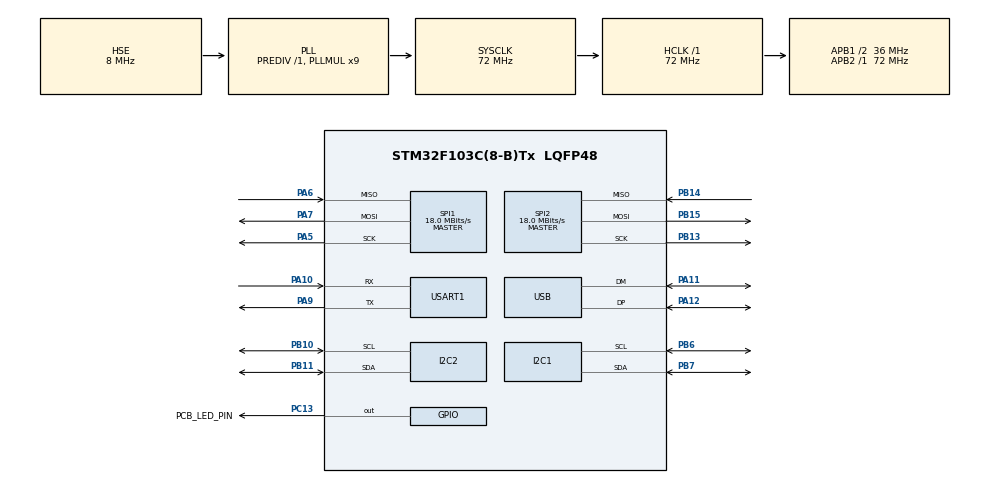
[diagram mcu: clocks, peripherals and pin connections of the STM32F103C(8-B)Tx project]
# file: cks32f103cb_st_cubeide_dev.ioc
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Dma.MEMTOMEM.0.Direction=DMA_MEMORY_TO_MEMORY
Dma.MEMTOMEM.0.Instance=DMA1_Channel1
Dma.MEMTOMEM.0.MemDataAlignment=DMA_MDATAALIGN_BYTE
Dma.MEMTOMEM.0.MemInc=DMA_MINC_ENABLE
Dma.MEMTOMEM.0.Mode=DMA_NORMAL
Dma.MEMTOMEM.0.PeriphDataAlignment=DMA_PDATAALIGN_BYTE
Dma.MEMTOMEM.0.PeriphInc=DMA_PINC_ENABLE
Dma.MEMTOMEM.0.Priority=DMA_PRIORITY_LOW
Dma.MEMTOMEM.1.Direction=DMA_MEMORY_TO_MEMORY
Dma.MEMTOMEM.1.Instance=DMA1_Channel2
Dma.MEMTOMEM.1.MemDataAlignment=DMA_MDATAALIGN_HALFWORD
Dma.MEMTOMEM.1.MemInc=DMA_MINC_ENABLE
Dma.MEMTOMEM.1.Mode=DMA_NORMAL
Dma.MEMTOMEM.1.PeriphDataAlignment=DMA_PDATAALIGN_HALFWORD
Dma.MEMTOMEM.1.PeriphInc=DMA_PINC_ENABLE
Dma.MEMTOMEM.1.Priority=DMA_PRIORITY_LOW
Dma.MEMTOMEM.2.Direction=DMA_MEMORY_TO_MEMORY
Dma.MEMTOMEM.2.Instance=DMA1_Channel3
Dma.MEMTOMEM.2.MemDataAlignment=DMA_MDATAALIGN_BYTE
Dma.MEMTOMEM.2.MemInc=DMA_MINC_ENABLE
Dma.MEMTOMEM.2.Mode=DMA_NORMAL
Dma.MEMTOMEM.2.PeriphDataAlignment=DMA_PDATAALIGN_WORD
Dma.MEMTOMEM.2.PeriphInc=DMA_PINC_ENABLE
Dma.MEMTOMEM.2.Priority=DMA_PRIORITY_LOW
Dma.Request0=MEMTOMEM
Dma.Request1=MEMTOMEM
Dma.Request2=MEMTOMEM
FREERTOS.Tasks01=defaultTask,24,128,StartDefaultTask,Default,NULL,Dynamic,NULL,NULL
I2C2.I2C_Mode=I2C_Fast
Mcu.Family=STM32F1
Mcu.Name=STM32F103C(8-B)Tx
Mcu.Package=LQFP48
NVIC.I2C1_EV_IRQn=true\:5\:0\:false\:false\:true\:true\:true\:true\:true
NVIC.I2C2_EV_IRQn=true\:5\:0\:false\:false\:true\:true\:true\:true\:true
NVIC.PriorityGroup=NVIC_PRIORITYGROUP_4
NVIC.SPI1_IRQn=true\:5\:0\:false\:false\:true\:true\:true\:true\:true
NVIC.SPI2_IRQn=true\:5\:0\:false\:false\:true\:true\:true\:true\:true
NVIC.TIM3_IRQn=true\:5\:0\:false\:false\:true\:true\:true\:true\:true
NVIC.TIM4_IRQn=true\:5\:0\:false\:false\:true\:true\:true\:true\:true
NVIC.USART1_IRQn=true\:5\:0\:false\:false\:true\:true\:true\:true\:true
NVIC.USB_LP_CAN1_RX0_IRQn=true\:5\:0\:false\:false\:true\:true\:false\:true\:true
PA10.Mode=Asynchronous
PA10.Signal=USART1_RX
PA11.Mode=Device
PA11.Signal=USB_DM
PA12.Mode=Device
PA12.Signal=USB_DP
PA13.Mode=Serial_Wire
PA13.Signal=SYS_JTMS-SWDIO
PA14.Mode=Serial_Wire
PA14.Signal=SYS_JTCK-SWCLK
PA5.Mode=Full_Duplex_Master
PA5.Signal=SPI1_SCK
PA6.Mode=Full_Duplex_Master
PA6.Signal=SPI1_MISO
PA7.Mode=Full_Duplex_Master
PA7.Signal=SPI1_MOSI
PA9.Mode=Asynchronous
PA9.Signal=USART1_TX
PB10.Mode=I2C
PB10.Signal=I2C2_SCL
PB11.Mode=I2C
PB11.Signal=I2C2_SDA
PB13.Mode=Full_Duplex_Master
PB13.Signal=SPI2_SCK
PB14.Mode=Full_Duplex_Master
PB14.Signal=SPI2_MISO
PB15.Mode=Full_Duplex_Master
PB15.Signal=SPI2_MOSI
PB6.Mode=I2C
PB6.Signal=I2C1_SCL
PB7.Mode=I2C
PB7.Signal=I2C1_SDA
PC13-TAMPER-RTC.GPIO_Label=PCB_LED_PIN
PC13-TAMPER-RTC.GPIO_ModeDefaultOutputPP=GPIO_MODE_OUTPUT_PP
PC13-TAMPER-RTC.Signal=GPIO_Output
PC14-OSC32_IN.Mode=LSE-External-Oscillator
PC14-OSC32_IN.Signal=RCC_OSC32_IN
PC15-OSC32_OUT.Mode=LSE-External-Oscillator
PC15-OSC32_OUT.Signal=RCC_OSC32_OUT
PD0-OSC_IN.Mode=HSE-External-Oscillator
PD0-OSC_IN.Signal=RCC_OSC_IN
PD1-OSC_OUT.Mode=HSE-External-Oscillator
PD1-OSC_OUT.Signal=RCC_OSC_OUT
ProjectManager.HeapSize=0x200
ProjectManager.StackSize=0x400
ProjectManager.TargetToolchain=STM32CubeIDE
RCC.AHBFreq_Value=72000000
RCC.APB1CLKDivider=RCC_HCLK_DIV2
RCC.APB1Freq_Value=36000000
RCC.APB1TimFreq_Value=72000000
RCC.APB2Freq_Value=72000000
RCC.APB2TimFreq_Value=72000000
RCC.HCLKFreq_Value=72000000
RCC.PLLMUL=RCC_PLL_MUL9
RCC.PLLSourceVirtual=RCC_PLLSOURCE_HSE
RCC.SYSCLKFreq_VALUE=72000000
RCC.SYSCLKSource=RCC_SYSCLKSOURCE_PLLCLK
RCC.USBFreq_Value=48000000
RCC.USBPrescaler=RCC_USBCLKSOURCE_PLL_DIV1_5
SPI1.BaudRatePrescaler=SPI_BAUDRATEPRESCALER_4
SPI1.CalculateBaudRate=18.0 MBits/s
SPI1.Direction=SPI_DIRECTION_2LINES
SPI1.Mode=SPI_MODE_MASTER
SPI1.VirtualType=VM_MASTER
SPI2.CalculateBaudRate=18.0 MBits/s
SPI2.Direction=SPI_DIRECTION_2LINES
SPI2.Mode=SPI_MODE_MASTER
SPI2.VirtualType=VM_MASTER
TIM1.AutoReloadPreload=TIM_AUTORELOAD_PRELOAD_ENABLE
TIM2.AutoReloadPreload=TIM_AUTORELOAD_PRELOAD_ENABLE
TIM3.AutoReloadPreload=TIM_AUTORELOAD_PRELOAD_ENABLE
TIM4.AutoReloadPreload=TIM_AUTORELOAD_PRELOAD_ENABLE
USART1.VirtualMode=VM_ASYNC
USB_DEVICE.CLASS_NAME_FS=CDC
USB_DEVICE.VirtualMode=Cdc
USB_DEVICE.VirtualModeFS=Cdc_FS
VP_FREERTOS_VS_CMSIS_V2.Mode=CMSIS_V2
VP_TIM1_VS_ClockSourceINT.Mode=Internal
VP_TIM2_VS_ClockSourceINT.Mode=Internal
VP_TIM3_VS_ClockSourceINT.Mode=Internal
VP_TIM4_VS_ClockSourceINT.Mode=Internal
VP_USB_DEVICE_VS_USB_DEVICE_CDC_FS.Mode=CDC_FS
board=custom

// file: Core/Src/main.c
/* USER CODE BEGIN Header */
/**
  ******************************************************************************
  * @file           : main.c
  * @brief          : Main program body
  ******************************************************************************
  * @attention
  *
  * Copyright (c) 2025 STMicroelectronics.
  * All rights reserved.
  *
  * This software is licensed under terms that can be found in the LICENSE file
  * in the root directory of this software component.
  * If no LICENSE file comes with this software, it is provided AS-IS.
  *
  ******************************************************************************
  */
/* USER CODE END Header */
#include "main.h"
#include "cmsis_os.h"
#include "usb_device.h"

I2C_HandleTypeDef hi2c1;
I2C_HandleTypeDef hi2c2;

SPI_HandleTypeDef hspi1;
SPI_HandleTypeDef hspi2;

TIM_HandleTypeDef htim1;
TIM_HandleTypeDef htim2;
TIM_HandleTypeDef htim3;
TIM_HandleTypeDef htim4;

UART_HandleTypeDef huart1;

DMA_HandleTypeDef hdma_memtomem_dma1_channel1;
DMA_HandleTypeDef hdma_memtomem_dma1_channel2;
DMA_HandleTypeDef hdma_memtomem_dma1_channel3;
/* Definitions for defaultTask */
osThreadId_t defaultTaskHandle;
const osThreadAttr_t defaultTask_attributes = {
  .name = "defaultTask",
  .stack_size = 128 * 4,
  .priority = (osPriority_t) osPriorityNormal,
};

void SystemClock_Config(void);
static void MX_GPIO_Init(void);
static void MX_DMA_Init(void);
static void MX_I2C1_Init(void);
static void MX_I2C2_Init(void);
static void MX_SPI1_Init(void);
static void MX_SPI2_Init(void);
static void MX_TIM1_Init(void);
static void MX_TIM2_Init(void);
static void MX_TIM3_Init(void);
static void MX_TIM4_Init(void);
static void MX_USART1_UART_Init(void);
void StartDefaultTask(void *argument);

int main(void)
{

  /* MCU Configuration--------------------------------------------------------*/

  /* Reset of all peripherals, Initializes the Flash interface and the Systick. */
  HAL_Init();

  /* Configure the system clock */
  SystemClock_Config();

  /* Initialize all configured peripherals */
  MX_GPIO_Init();
  MX_DMA_Init();
  MX_I2C1_Init();
  MX_I2C2_Init();
  MX_SPI1_Init();
  MX_SPI2_Init();
  MX_TIM1_Init();
  MX_TIM2_Init();
  MX_TIM3_Init();
  MX_TIM4_Init();
  MX_USART1_UART_Init();

  /* Init scheduler */
  osKernelInitialize();

  /* Create the thread(s) */
  /* creation of defaultTask */
  defaultTaskHandle = osThreadNew(StartDefaultTask, NULL, &defaultTask_attributes);

  /* Start scheduler */
  osKernelStart();

  /* We should never get here as control is now taken by the scheduler */

  /* Infinite loop */
  while (1)
  {

  }
}

void SystemClock_Config(void)
{
  RCC_OscInitTypeDef RCC_OscInitStruct = {0};
  RCC_ClkInitTypeDef RCC_ClkInitStruct = {0};
  RCC_PeriphCLKInitTypeDef PeriphClkInit = {0};

  /** Initializes the RCC Oscillators according to the specified parameters
  * in the RCC_OscInitTypeDef structure.
  */
  RCC_OscInitStruct.OscillatorType = RCC_OSCILLATORTYPE_HSE;
  RCC_OscInitStruct.HSEState = RCC_HSE_ON;
  RCC_OscInitStruct.HSEPredivValue = RCC_HSE_PREDIV_DIV1;
  RCC_OscInitStruct.HSIState = RCC_HSI_ON;
  RCC_OscInitStruct.PLL.PLLState = RCC_PLL_ON;
  RCC_OscInitStruct.PLL.PLLSource = RCC_PLLSOURCE_HSE;
  RCC_OscInitStruct.PLL.PLLMUL = RCC_PLL_MUL9;
  if (HAL_RCC_OscConfig(&RCC_OscInitStruct) != HAL_OK)
  {
    Error_Handler();
  }

  /** Initializes the CPU, AHB and APB buses clocks
  */
  RCC_ClkInitStruct.ClockType = RCC_CLOCKTYPE_HCLK|RCC_CLOCKTYPE_SYSCLK
                              |RCC_CLOCKTYPE_PCLK1|RCC_CLOCKTYPE_PCLK2;
  RCC_ClkInitStruct.SYSCLKSource = RCC_SYSCLKSOURCE_PLLCLK;
  RCC_ClkInitStruct.AHBCLKDivider = RCC_SYSCLK_DIV1;
  RCC_ClkInitStruct.APB1CLKDivider = RCC_HCLK_DIV2;
  RCC_ClkInitStruct.APB2CLKDivider = RCC_HCLK_DIV1;

  if (HAL_RCC_ClockConfig(&RCC_ClkInitStruct, FLASH_LATENCY_2) != HAL_OK)
  {
    Error_Handler();
  }
  PeriphClkInit.PeriphClockSelection = RCC_PERIPHCLK_USB;
  PeriphClkInit.UsbClockSelection = RCC_USBCLKSOURCE_PLL_DIV1_5;
  if (HAL_RCCEx_PeriphCLKConfig(&PeriphClkInit) != HAL_OK)
  {
    Error_Handler();
  }
}

static void MX_I2C1_Init(void)
{

  hi2c1.Instance = I2C1;
  hi2c1.Init.ClockSpeed = 100000;
  hi2c1.Init.DutyCycle = I2C_DUTYCYCLE_2;
  hi2c1.Init.OwnAddress1 = 0;
  hi2c1.Init.AddressingMode = I2C_ADDRESSINGMODE_7BIT;
  hi2c1.Init.DualAddressMode = I2C_DUALADDRESS_DISABLE;
  hi2c1.Init.OwnAddress2 = 0;
  hi2c1.Init.GeneralCallMode = I2C_GENERALCALL_DISABLE;
  hi2c1.Init.NoStretchMode = I2C_NOSTRETCH_DISABLE;
  if (HAL_I2C_Init(&hi2c1) != HAL_OK)
  {
    Error_Handler();
  }

}

static void MX_I2C2_Init(void)
{

  hi2c2.Instance = I2C2;
  hi2c2.Init.ClockSpeed = 400000;
  hi2c2.Init.DutyCycle = I2C_DUTYCYCLE_2;
  hi2c2.Init.OwnAddress1 = 0;
  hi2c2.Init.AddressingMode = I2C_ADDRESSINGMODE_7BIT;
  hi2c2.Init.DualAddressMode = I2C_DUALADDRESS_DISABLE;
  hi2c2.Init.OwnAddress2 = 0;
  hi2c2.Init.GeneralCallMode = I2C_GENERALCALL_DISABLE;
  hi2c2.Init.NoStretchMode = I2C_NOSTRETCH_DISABLE;
  if (HAL_I2C_Init(&hi2c2) != HAL_OK)
  {
    Error_Handler();
  }

}

static void MX_SPI1_Init(void)
{

  /* SPI1 parameter configuration*/
  hspi1.Instance = SPI1;
  hspi1.Init.Mode = SPI_MODE_MASTER;
  hspi1.Init.Direction = SPI_DIRECTION_2LINES;
  hspi1.Init.DataSize = SPI_DATASIZE_8BIT;
  hspi1.Init.CLKPolarity = SPI_POLARITY_LOW;
  hspi1.Init.CLKPhase = SPI_PHASE_1EDGE;
  hspi1.Init.NSS = SPI_NSS_SOFT;
  hspi1.Init.BaudRatePrescaler = SPI_BAUDRATEPRESCALER_4;
  hspi1.Init.FirstBit = SPI_FIRSTBIT_MSB;
  hspi1.Init.TIMode = SPI_TIMODE_DISABLE;
  hspi1.Init.CRCCalculation = SPI_CRCCALCULATION_DISABLE;
  hspi1.Init.CRCPolynomial = 10;
  if (HAL_SPI_Init(&hspi1) != HAL_OK)
  {
    Error_Handler();
  }

}

static void MX_SPI2_Init(void)
{

  /* SPI2 parameter configuration*/
  hspi2.Instance = SPI2;
  hspi2.Init.Mode = SPI_MODE_MASTER;
  hspi2.Init.Direction = SPI_DIRECTION_2LINES;
  hspi2.Init.DataSize = SPI_DATASIZE_8BIT;
  hspi2.Init.CLKPolarity = SPI_POLARITY_LOW;
  hspi2.Init.CLKPhase = SPI_PHASE_1EDGE;
  hspi2.Init.NSS = SPI_NSS_SOFT;
  hspi2.Init.BaudRatePrescaler = SPI_BAUDRATEPRESCALER_2;
  hspi2.Init.FirstBit = SPI_FIRSTBIT_MSB;
  hspi2.Init.TIMode = SPI_TIMODE_DISABLE;
  hspi2.Init.CRCCalculation = SPI_CRCCALCULATION_DISABLE;
  hspi2.Init.CRCPolynomial = 10;
  if (HAL_SPI_Init(&hspi2) != HAL_OK)
  {
    Error_Handler();
  }

}

static void MX_TIM1_Init(void)
{

  TIM_ClockConfigTypeDef sClockSourceConfig = {0};
  TIM_MasterConfigTypeDef sMasterConfig = {0};

  htim1.Instance = TIM1;
  htim1.Init.Prescaler = 0;
  htim1.Init.CounterMode = TIM_COUNTERMODE_UP;
  htim1.Init.Period = 65535;
  htim1.Init.ClockDivision = TIM_CLOCKDIVISION_DIV1;
  htim1.Init.RepetitionCounter = 0;
  htim1.Init.AutoReloadPreload = TIM_AUTORELOAD_PRELOAD_ENABLE;
  if (HAL_TIM_Base_Init(&htim1) != HAL_OK)
  {
    Error_Handler();
  }
  sClockSourceConfig.ClockSource = TIM_CLOCKSOURCE_INTERNAL;
  if (HAL_TIM_ConfigClockSource(&htim1, &sClockSourceConfig) != HAL_OK)
  {
    Error_Handler();
  }
  sMasterConfig.MasterOutputTrigger = TIM_TRGO_RESET;
  sMasterConfig.MasterSlaveMode = TIM_MASTERSLAVEMODE_DISABLE;
  if (HAL_TIMEx_MasterConfigSynchronization(&htim1, &sMasterConfig) != HAL_OK)
  {
    Error_Handler();
  }

}

static void MX_TIM2_Init(void)
{

  TIM_ClockConfigTypeDef sClockSourceConfig = {0};
  TIM_MasterConfigTypeDef sMasterConfig = {0};

  htim2.Instance = TIM2;
  htim2.Init.Prescaler = 0;
  htim2.Init.CounterMode = TIM_COUNTERMODE_UP;
  htim2.Init.Period = 65535;
  htim2.Init.ClockDivision = TIM_CLOCKDIVISION_DIV1;
  htim2.Init.AutoReloadPreload = TIM_AUTORELOAD_PRELOAD_ENABLE;
  if (HAL_TIM_Base_Init(&htim2) != HAL_OK)
  {
    Error_Handler();
  }
  sClockSourceConfig.ClockSource = TIM_CLOCKSOURCE_INTERNAL;
  if (HAL_TIM_ConfigClockSource(&htim2, &sClockSourceConfig) != HAL_OK)
  {
    Error_Handler();
  }
  sMasterConfig.MasterOutputTrigger = TIM_TRGO_RESET;
  sMasterConfig.MasterSlaveMode = TIM_MASTERSLAVEMODE_DISABLE;
  if (HAL_TIMEx_MasterConfigSynchronization(&htim2, &sMasterConfig) != HAL_OK)
  {
    Error_Handler();
  }

}

static void MX_TIM3_Init(void)
{

  TIM_ClockConfigTypeDef sClockSourceConfig = {0};
  TIM_MasterConfigTypeDef sMasterConfig = {0};

  htim3.Instance = TIM3;
  htim3.Init.Prescaler = 0;
  htim3.Init.CounterMode = TIM_COUNTERMODE_UP;
  htim3.Init.Period = 65535;
  htim3.Init.ClockDivision = TIM_CLOCKDIVISION_DIV1;
  htim3.Init.AutoReloadPreload = TIM_AUTORELOAD_PRELOAD_ENABLE;
  if (HAL_TIM_Base_Init(&htim3) != HAL_OK)
  {
    Error_Handler();
  }
  sClockSourceConfig.ClockSource = TIM_CLOCKSOURCE_INTERNAL;
  if (HAL_TIM_ConfigClockSource(&htim3, &sClockSourceConfig) != HAL_OK)
  {
    Error_Handler();
  }
  sMasterConfig.MasterOutputTrigger = TIM_TRGO_RESET;
  sMasterConfig.MasterSlaveMode = TIM_MASTERSLAVEMODE_DISABLE;
  if (HAL_TIMEx_MasterConfigSynchronization(&htim3, &sMasterConfig) != HAL_OK)
  {
    Error_Handler();
  }

}

static void MX_TIM4_Init(void)
{

  TIM_ClockConfigTypeDef sClockSourceConfig = {0};
  TIM_MasterConfigTypeDef sMasterConfig = {0};

  htim4.Instance = TIM4;
  htim4.Init.Prescaler = 0;
  htim4.Init.CounterMode = TIM_COUNTERMODE_UP;
  htim4.Init.Period = 65535;
  htim4.Init.ClockDivision = TIM_CLOCKDIVISION_DIV1;
  htim4.Init.AutoReloadPreload = TIM_AUTORELOAD_PRELOAD_ENABLE;
  if (HAL_TIM_Base_Init(&htim4) != HAL_OK)
  {
    Error_Handler();
  }
  sClockSourceConfig.ClockSource = TIM_CLOCKSOURCE_INTERNAL;
  if (HAL_TIM_ConfigClockSource(&htim4, &sClockSourceConfig) != HAL_OK)
  {
    Error_Handler();
  }
  sMasterConfig.MasterOutputTrigger = TIM_TRGO_RESET;
  sMasterConfig.MasterSlaveMode = TIM_MASTERSLAVEMODE_DISABLE;
  if (HAL_TIMEx_MasterConfigSynchronization(&htim4, &sMasterConfig) != HAL_OK)
  {
    Error_Handler();
  }

}

static void MX_USART1_UART_Init(void)
{

  huart1.Instance = USART1;
  huart1.Init.BaudRate = 115200;
  huart1.Init.WordLength = UART_WORDLENGTH_8B;
  huart1.Init.StopBits = UART_STOPBITS_1;
  huart1.Init.Parity = UART_PARITY_NONE;
  huart1.Init.Mode = UART_MODE_TX_RX;
  huart1.Init.HwFlowCtl = UART_HWCONTROL_NONE;
  huart1.Init.OverSampling = UART_OVERSAMPLING_16;
  if (HAL_UART_Init(&huart1) != HAL_OK)
  {
    Error_Handler();
  }

}

static void MX_DMA_Init(void)
{

  /* DMA controller clock enable */
  __HAL_RCC_DMA1_CLK_ENABLE();

  /* Configure DMA request hdma_memtomem_dma1_channel1 on DMA1_Channel1 */
  hdma_memtomem_dma1_channel1.Instance = DMA1_Channel1;
  hdma_memtomem_dma1_channel1.Init.Direction = DMA_MEMORY_TO_MEMORY;
  hdma_memtomem_dma1_channel1.Init.PeriphInc = DMA_PINC_ENABLE;
  hdma_memtomem_dma1_channel1.Init.MemInc = DMA_MINC_ENABLE;
  hdma_memtomem_dma1_channel1.Init.PeriphDataAlignment = DMA_PDATAALIGN_BYTE;
  hdma_memtomem_dma1_channel1.Init.MemDataAlignment = DMA_MDATAALIGN_BYTE;
  hdma_memtomem_dma1_channel1.Init.Mode = DMA_NORMAL;
  hdma_memtomem_dma1_channel1.Init.Priority = DMA_PRIORITY_LOW;
  if (HAL_DMA_Init(&hdma_memtomem_dma1_channel1) != HAL_OK)
  {
    Error_Handler( );
  }

  /* Configure DMA request hdma_memtomem_dma1_channel2 on DMA1_Channel2 */
  hdma_memtomem_dma1_channel2.Instance = DMA1_Channel2;
  hdma_memtomem_dma1_channel2.Init.Direction = DMA_MEMORY_TO_MEMORY;
  hdma_memtomem_dma1_channel2.Init.PeriphInc = DMA_PINC_ENABLE;
  hdma_memtomem_dma1_channel2.Init.MemInc = DMA_MINC_ENABLE;
  hdma_memtomem_dma1_channel2.Init.PeriphDataAlignment = DMA_PDATAALIGN_HALFWORD;
  hdma_memtomem_dma1_channel2.Init.MemDataAlignment = DMA_MDATAALIGN_HALFWORD;
  hdma_memtomem_dma1_channel2.Init.Mode = DMA_NORMAL;
  hdma_memtomem_dma1_channel2.Init.Priority = DMA_PRIORITY_LOW;
  if (HAL_DMA_Init(&hdma_memtomem_dma1_channel2) != HAL_OK)
  {
    Error_Handler( );
  }

  /* Configure DMA request hdma_memtomem_dma1_channel3 on DMA1_Channel3 */
  hdma_memtomem_dma1_channel3.Instance = DMA1_Channel3;
  hdma_memtomem_dma1_channel3.Init.Direction = DMA_MEMORY_TO_MEMORY;
  hdma_memtomem_dma1_channel3.Init.PeriphInc = DMA_PINC_ENABLE;
  hdma_memtomem_dma1_channel3.Init.MemInc = DMA_MINC_ENABLE;
  hdma_memtomem_dma1_channel3.Init.PeriphDataAlignment = DMA_PDATAALIGN_WORD;
  hdma_memtomem_dma1_channel3.Init.MemDataAlignment = DMA_MDATAALIGN_BYTE;
  hdma_memtomem_dma1_channel3.Init.Mode = DMA_NORMAL;
  hdma_memtomem_dma1_channel3.Init.Priority = DMA_PRIORITY_LOW;
  if (HAL_DMA_Init(&hdma_memtomem_dma1_channel3) != HAL_OK)
  {
    Error_Handler( );
  }

}

static void MX_GPIO_Init(void)
{
  GPIO_InitTypeDef GPIO_InitStruct = {0};

  /* GPIO Ports Clock Enable */
  __HAL_RCC_GPIOC_CLK_ENABLE();
  __HAL_RCC_GPIOD_CLK_ENABLE();
  __HAL_RCC_GPIOA_CLK_ENABLE();
  __HAL_RCC_GPIOB_CLK_ENABLE();

  /*Configure GPIO pin Output Level */
  HAL_GPIO_WritePin(PCB_LED_PIN_GPIO_Port, PCB_LED_PIN_Pin, GPIO_PIN_RESET);

  /*Configure GPIO pin : PCB_LED_PIN_Pin */
  GPIO_InitStruct.Pin = PCB_LED_PIN_Pin;
  GPIO_InitStruct.Mode = GPIO_MODE_OUTPUT_PP;
  GPIO_InitStruct.Pull = GPIO_NOPULL;
  GPIO_InitStruct.Speed = GPIO_SPEED_FREQ_LOW;
  HAL_GPIO_Init(PCB_LED_PIN_GPIO_Port, &GPIO_InitStruct);

}

void StartDefaultTask(void *argument)
{
  /* init code for USB_DEVICE */
  MX_USB_DEVICE_Init();
  /* USER CODE BEGIN 5 */
  /* Infinite loop */
  for(;;)
  {
    HAL_GPIO_WritePin(PCB_LED_PIN_GPIO_Port, PCB_LED_PIN_Pin, GPIO_PIN_RESET);
    osDelay(1000);
    HAL_GPIO_WritePin(PCB_LED_PIN_GPIO_Port, PCB_LED_PIN_Pin, GPIO_PIN_SET);
    osDelay(1000);
  }
  /* USER CODE END 5 */
}

void Error_Handler(void)
{
  __disable_irq();
  while (1)
  {
  }
}
